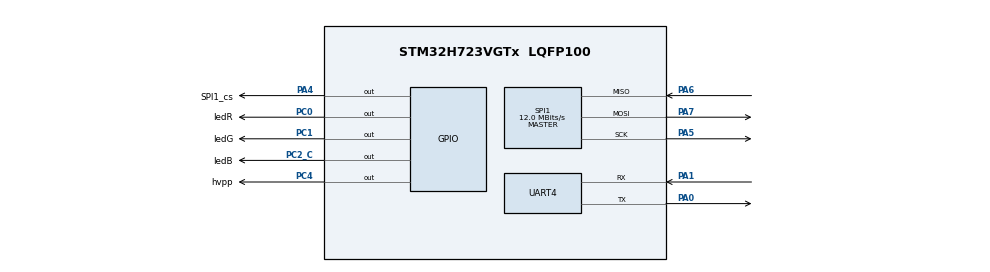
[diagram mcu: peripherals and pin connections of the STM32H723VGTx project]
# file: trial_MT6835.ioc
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CORTEX_M7.default_mode_Activation=1
Mcu.Family=STM32H7
Mcu.Name=STM32H723VGTx
Mcu.Package=LQFP100
NVIC.PriorityGroup=NVIC_PRIORITYGROUP_4
PA0.Mode=Asynchronous
PA0.Signal=UART4_TX
PA1.Mode=Asynchronous
PA1.Signal=UART4_RX
PA4.GPIO_Label=SPI1_cs
PA4.GPIO_PuPd=GPIO_PULLUP
PA4.Signal=GPIO_Output
PA5.Mode=Full_Duplex_Master
PA5.Signal=SPI1_SCK
PA6.Mode=Full_Duplex_Master
PA6.Signal=SPI1_MISO
PA7.Mode=Full_Duplex_Master
PA7.Signal=SPI1_MOSI
PC0.GPIO_Label=ledR
PC0.Signal=GPIO_Output
PC1.GPIO_Label=ledG
PC1.Signal=GPIO_Output
PC2_C.GPIO_Label=ledB
PC2_C.Signal=GPIO_Output
PC4.GPIO_Label=hvpp
PC4.Signal=GPIO_Output
ProjectManager.HeapSize=0x200
ProjectManager.StackSize=0x400
ProjectManager.TargetToolchain=CMake
RCC.ADCFreq_Value=48000000
RCC.APB1Freq_Value=137500000
RCC.APB2Freq_Value=137500000
RCC.APB3Freq_Value=137500000
RCC.APB4Freq_Value=137500000
RCC.CortexFreq_Value=275000000
RCC.D1PPRE=RCC_APB3_DIV2
RCC.D2PPRE1=RCC_APB1_DIV2
RCC.D2PPRE2=RCC_APB2_DIV2
RCC.D3PPRE=RCC_APB4_DIV2
RCC.DIVM1=4
RCC.DIVM2=4
RCC.DIVN1=17
RCC.DIVN2=12
RCC.DIVP1=1
RCC.DIVP2=4
RCC.DIVQ1=3
RCC.HCLKFreq_Value=275000000
RCC.PLL2FRACN=0
RCC.PLLFRACN=1536
RCC.SPI123CLockSelection=RCC_SPI123CLKSOURCE_PLL2
RCC.SYSCLKFreq_VALUE=275000000
RCC.SYSCLKSource=RCC_SYSCLKSOURCE_PLLCLK
RCC.USART234578CLockSelection=RCC_USART234578CLKSOURCE_HSI
RCC.USBFreq_Value=91666666.66666667
SPI1.BaudRatePrescaler=SPI_BAUDRATEPRESCALER_4
SPI1.CLKPhase=SPI_PHASE_2EDGE
SPI1.CLKPolarity=SPI_POLARITY_HIGH
SPI1.CRCCalculation=SPI_CRCCALCULATION_DISABLE
SPI1.CalculateBaudRate=12.0 MBits/s
SPI1.DataSize=SPI_DATASIZE_8BIT
SPI1.Direction=SPI_DIRECTION_2LINES
SPI1.FirstBit=SPI_FIRSTBIT_MSB
SPI1.Mode=SPI_MODE_MASTER
SPI1.NSSPMode=SPI_NSS_PULSE_DISABLE
SPI1.VirtualType=VM_MASTER
VP_MEMORYMAP_VS_MEMORYMAP.Mode=CurAppReg
board=custom

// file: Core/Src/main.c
/* USER CODE BEGIN Header */
/**
  ******************************************************************************
  * @file           : main.c
  * @brief          : Main program body
  ******************************************************************************
  * @attention
  *
  * Copyright (c) 2025 STMicroelectronics.
  * All rights reserved.
  *
  * This software is licensed under terms that can be found in the LICENSE file
  * in the root directory of this software component.
  * If no LICENSE file comes with this software, it is provided AS-IS.
  *
  ******************************************************************************
  */
/* USER CODE END Header */
#include "main.h"

SPI_HandleTypeDef hspi1;

UART_HandleTypeDef huart4;

void SystemClock_Config(void);
static void MPU_Config(void);
static void MX_GPIO_Init(void);
static void MX_SPI1_Init(void);
static void MX_UART4_Init(void);

int main(void)
{

  /* MPU Configuration--------------------------------------------------------*/
  MPU_Config();

  /* MCU Configuration--------------------------------------------------------*/

  /* Reset of all peripherals, Initializes the Flash interface and the Systick. */
  HAL_Init();

  /* Configure the system clock */
  SystemClock_Config();

  /* Initialize all configured peripherals */
  MX_GPIO_Init();
  MX_SPI1_Init();
  MX_UART4_Init();

  /* Infinite loop */
  /* USER CODE BEGIN WHILE */

  char *expCommand[2] = {0x50, 0x00}; //读取位置
  char *get = 0x00;

  while (1)
  {
    /* USER CODE END WHILE */
    HAL_GPIO_WritePin(SPI1_cs_GPIO_Port, SPI1_cs_Pin, 0);
    HAL_SPI_Transmit(&hspi1, expCommand, 2, 100);

    HAL_GPIO_WritePin(SPI1_cs_GPIO_Port, SPI1_cs_Pin, 1);

    HAL_UART_Transmit(&huart4, expCommand, 2, 1000);
    HAL_Delay(1000);
  }
}

void SystemClock_Config(void)
{
  RCC_OscInitTypeDef RCC_OscInitStruct = {0};
  RCC_ClkInitTypeDef RCC_ClkInitStruct = {0};

  /** Supply configuration update enable
  */
  HAL_PWREx_ConfigSupply(PWR_LDO_SUPPLY);

  /** Configure the main internal regulator output voltage
  */
  __HAL_PWR_VOLTAGESCALING_CONFIG(PWR_REGULATOR_VOLTAGE_SCALE0);

  while(!__HAL_PWR_GET_FLAG(PWR_FLAG_VOSRDY)) {}

  /** Initializes the RCC Oscillators according to the specified parameters
  * in the RCC_OscInitTypeDef structure.
  */
  RCC_OscInitStruct.OscillatorType = RCC_OSCILLATORTYPE_HSI;
  RCC_OscInitStruct.HSIState = RCC_HSI_DIV1;
  RCC_OscInitStruct.HSICalibrationValue = 64;
  RCC_OscInitStruct.PLL.PLLState = RCC_PLL_ON;
  RCC_OscInitStruct.PLL.PLLSource = RCC_PLLSOURCE_HSI;
  RCC_OscInitStruct.PLL.PLLM = 4;
  RCC_OscInitStruct.PLL.PLLN = 17;
  RCC_OscInitStruct.PLL.PLLP = 1;
  RCC_OscInitStruct.PLL.PLLQ = 3;
  RCC_OscInitStruct.PLL.PLLR = 2;
  RCC_OscInitStruct.PLL.PLLRGE = RCC_PLL1VCIRANGE_3;
  RCC_OscInitStruct.PLL.PLLVCOSEL = RCC_PLL1VCOWIDE;
  RCC_OscInitStruct.PLL.PLLFRACN = 1536;
  if (HAL_RCC_OscConfig(&RCC_OscInitStruct) != HAL_OK)
  {
    Error_Handler();
  }

  /** Initializes the CPU, AHB and APB buses clocks
  */
  RCC_ClkInitStruct.ClockType = RCC_CLOCKTYPE_HCLK|RCC_CLOCKTYPE_SYSCLK
                              |RCC_CLOCKTYPE_PCLK1|RCC_CLOCKTYPE_PCLK2
                              |RCC_CLOCKTYPE_D3PCLK1|RCC_CLOCKTYPE_D1PCLK1;
  RCC_ClkInitStruct.SYSCLKSource = RCC_SYSCLKSOURCE_PLLCLK;
  RCC_ClkInitStruct.SYSCLKDivider = RCC_SYSCLK_DIV1;
  RCC_ClkInitStruct.AHBCLKDivider = RCC_HCLK_DIV1;
  RCC_ClkInitStruct.APB3CLKDivider = RCC_APB3_DIV2;
  RCC_ClkInitStruct.APB1CLKDivider = RCC_APB1_DIV2;
  RCC_ClkInitStruct.APB2CLKDivider = RCC_APB2_DIV2;
  RCC_ClkInitStruct.APB4CLKDivider = RCC_APB4_DIV2;

  if (HAL_RCC_ClockConfig(&RCC_ClkInitStruct, FLASH_LATENCY_3) != HAL_OK)
  {
    Error_Handler();
  }
}

static void MX_SPI1_Init(void)
{

  /* SPI1 parameter configuration*/
  hspi1.Instance = SPI1;
  hspi1.Init.Mode = SPI_MODE_MASTER;
  hspi1.Init.Direction = SPI_DIRECTION_2LINES;
  hspi1.Init.DataSize = SPI_DATASIZE_8BIT;
  hspi1.Init.CLKPolarity = SPI_POLARITY_HIGH;
  hspi1.Init.CLKPhase = SPI_PHASE_2EDGE;
  hspi1.Init.NSS = SPI_NSS_SOFT;
  hspi1.Init.BaudRatePrescaler = SPI_BAUDRATEPRESCALER_4;
  hspi1.Init.FirstBit = SPI_FIRSTBIT_MSB;
  hspi1.Init.TIMode = SPI_TIMODE_DISABLE;
  hspi1.Init.CRCCalculation = SPI_CRCCALCULATION_DISABLE;
  hspi1.Init.CRCPolynomial = 0x0;
  hspi1.Init.NSSPMode = SPI_NSS_PULSE_DISABLE;
  hspi1.Init.NSSPolarity = SPI_NSS_POLARITY_LOW;
  hspi1.Init.FifoThreshold = SPI_FIFO_THRESHOLD_01DATA;
  hspi1.Init.TxCRCInitializationPattern = SPI_CRC_INITIALIZATION_ALL_ZERO_PATTERN;
  hspi1.Init.RxCRCInitializationPattern = SPI_CRC_INITIALIZATION_ALL_ZERO_PATTERN;
  hspi1.Init.MasterSSIdleness = SPI_MASTER_SS_IDLENESS_00CYCLE;
  hspi1.Init.MasterInterDataIdleness = SPI_MASTER_INTERDATA_IDLENESS_00CYCLE;
  hspi1.Init.MasterReceiverAutoSusp = SPI_MASTER_RX_AUTOSUSP_DISABLE;
  hspi1.Init.MasterKeepIOState = SPI_MASTER_KEEP_IO_STATE_DISABLE;
  hspi1.Init.IOSwap = SPI_IO_SWAP_DISABLE;
  if (HAL_SPI_Init(&hspi1) != HAL_OK)
  {
    Error_Handler();
  }

}

static void MX_UART4_Init(void)
{

  huart4.Instance = UART4;
  huart4.Init.BaudRate = 115200;
  huart4.Init.WordLength = UART_WORDLENGTH_8B;
  huart4.Init.StopBits = UART_STOPBITS_1;
  huart4.Init.Parity = UART_PARITY_NONE;
  huart4.Init.Mode = UART_MODE_TX_RX;
  huart4.Init.HwFlowCtl = UART_HWCONTROL_NONE;
  huart4.Init.OverSampling = UART_OVERSAMPLING_16;
  huart4.Init.OneBitSampling = UART_ONE_BIT_SAMPLE_DISABLE;
  huart4.Init.ClockPrescaler = UART_PRESCALER_DIV1;
  huart4.AdvancedInit.AdvFeatureInit = UART_ADVFEATURE_NO_INIT;
  if (HAL_UART_Init(&huart4) != HAL_OK)
  {
    Error_Handler();
  }
  if (HAL_UARTEx_SetTxFifoThreshold(&huart4, UART_TXFIFO_THRESHOLD_1_8) != HAL_OK)
  {
    Error_Handler();
  }
  if (HAL_UARTEx_SetRxFifoThreshold(&huart4, UART_RXFIFO_THRESHOLD_1_8) != HAL_OK)
  {
    Error_Handler();
  }
  if (HAL_UARTEx_DisableFifoMode(&huart4) != HAL_OK)
  {
    Error_Handler();
  }

}

static void MX_GPIO_Init(void)
{
  GPIO_InitTypeDef GPIO_InitStruct = {0};

  /* GPIO Ports Clock Enable */
  __HAL_RCC_GPIOC_CLK_ENABLE();
  __HAL_RCC_GPIOA_CLK_ENABLE();

  /*Configure GPIO pin Output Level */
  HAL_GPIO_WritePin(GPIOC, ledR_Pin|ledG_Pin|ledB_Pin|hvpp_Pin, GPIO_PIN_RESET);

  /*Configure GPIO pin Output Level */
  HAL_GPIO_WritePin(SPI1_cs_GPIO_Port, SPI1_cs_Pin, GPIO_PIN_RESET);

  /*Configure GPIO pins : ledR_Pin ledG_Pin ledB_Pin hvpp_Pin */
  GPIO_InitStruct.Pin = ledR_Pin|ledG_Pin|ledB_Pin|hvpp_Pin;
  GPIO_InitStruct.Mode = GPIO_MODE_OUTPUT_PP;
  GPIO_InitStruct.Pull = GPIO_NOPULL;
  GPIO_InitStruct.Speed = GPIO_SPEED_FREQ_LOW;
  HAL_GPIO_Init(GPIOC, &GPIO_InitStruct);

  /*Configure GPIO pin : SPI1_cs_Pin */
  GPIO_InitStruct.Pin = SPI1_cs_Pin;
  GPIO_InitStruct.Mode = GPIO_MODE_OUTPUT_PP;
  GPIO_InitStruct.Pull = GPIO_PULLUP;
  GPIO_InitStruct.Speed = GPIO_SPEED_FREQ_LOW;
  HAL_GPIO_Init(SPI1_cs_GPIO_Port, &GPIO_InitStruct);

  /*AnalogSwitch Config */
  HAL_SYSCFG_AnalogSwitchConfig(SYSCFG_SWITCH_PC2, SYSCFG_SWITCH_PC2_CLOSE);

}

 /* MPU Configuration */

void MPU_Config(void)
{
  MPU_Region_InitTypeDef MPU_InitStruct = {0};

  /* Disables the MPU */
  HAL_MPU_Disable();

  /** Initializes and configures the Region and the memory to be protected
  */
  MPU_InitStruct.Enable = MPU_REGION_ENABLE;
  MPU_InitStruct.Number = MPU_REGION_NUMBER0;
  MPU_InitStruct.BaseAddress = 0x0;
  MPU_InitStruct.Size = MPU_REGION_SIZE_4GB;
  MPU_InitStruct.SubRegionDisable = 0x87;
  MPU_InitStruct.TypeExtField = MPU_TEX_LEVEL0;
  MPU_InitStruct.AccessPermission = MPU_REGION_NO_ACCESS;
  MPU_InitStruct.DisableExec = MPU_INSTRUCTION_ACCESS_DISABLE;
  MPU_InitStruct.IsShareable = MPU_ACCESS_SHAREABLE;
  MPU_InitStruct.IsCacheable = MPU_ACCESS_NOT_CACHEABLE;
  MPU_InitStruct.IsBufferable = MPU_ACCESS_NOT_BUFFERABLE;

  HAL_MPU_ConfigRegion(&MPU_InitStruct);
  /* Enables the MPU */
  HAL_MPU_Enable(MPU_PRIVILEGED_DEFAULT);

}

void Error_Handler(void)
{
  __disable_irq();
  while (1)
  {
  }
}
